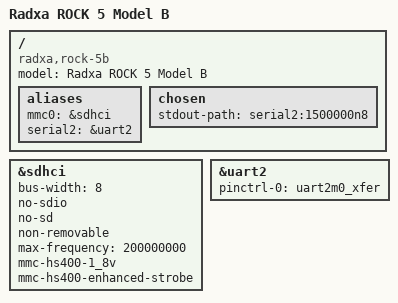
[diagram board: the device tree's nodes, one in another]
// SPDX-License-Identifier: (GPL-2.0+ OR MIT)

/dts-v1/;

#include "rk3588.dtsi"

/ {
	model = "Radxa ROCK 5 Model B";
	compatible = "radxa,rock-5b", "rockchip,rk3588";

	aliases {
		mmc0 = &sdhci;
		serial2 = &uart2;
	};

	chosen {
		stdout-path = "serial2:1500000n8";
	};
};

&sdhci {
	bus-width = <8>;
	no-sdio;
	no-sd;
	non-removable;
	max-frequency = <200000000>;
	mmc-hs400-1_8v;
	mmc-hs400-enhanced-strobe;
	status = "okay";
};

&uart2 {
	pinctrl-0 = <&uart2m0_xfer>;
	status = "okay";
};
